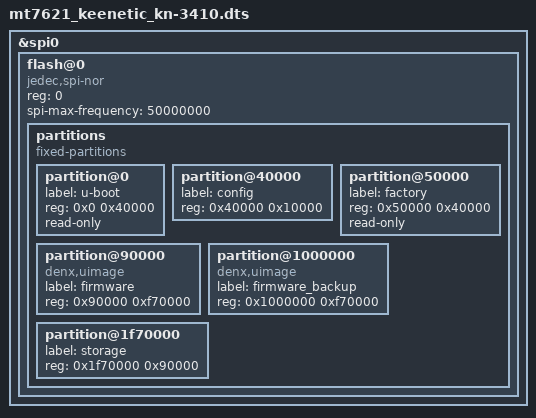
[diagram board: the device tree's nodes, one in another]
/dts-v1/;
#include "mt7621.dtsi"

&spi0 {
   status = "okay";

   flash@0 {
       compatible = "jedec,spi-nor";
       reg = <0>;
       spi-max-frequency = <50000000>;

       partitions {
           compatible = "fixed-partitions";
           #address-cells = <1>;
           #size-cells = <1>;

           partition@0 {
               label = "u-boot";
               reg = <0x0 0x40000>;
               read-only;
           };

           partition@40000 {
               label = "config";
               reg = <0x40000 0x10000>;
           };

           partition@50000 {
               label = "factory";
               reg = <0x50000 0x40000>;
               read-only;
           };

           partition@90000 {
               label = "firmware";
               reg = <0x90000 0xf70000>;
               compatible = "denx,uimage";
           };

           partition@1000000 {
               label = "firmware_backup";
               reg = <0x1000000 0xf70000>;
               compatible = "denx,uimage";
           };

           partition@1f70000 {
               label = "storage";
               reg = <0x1f70000 0x90000>;
           };
       };
   };
};
